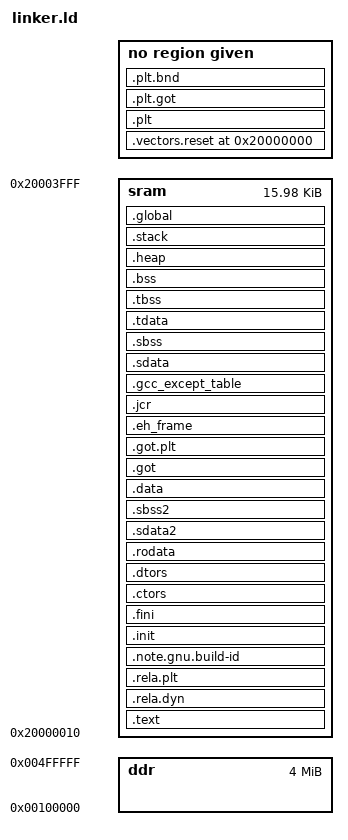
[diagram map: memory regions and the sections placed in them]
_STACK_SIZE = DEFINED(_STACK_SIZE) ? _STACK_SIZE : 0x400;
_HEAP_SIZE = DEFINED(_HEAP_SIZE) ? _HEAP_SIZE : 0x800;

/* Define Memories in the system */

MEMORY
{
   sram : ORIGIN = 0x20000010, LENGTH = 0x3FF0
   ddr : ORIGIN = 0x100000, LENGTH = 4M
}

/* Specify the default entry point to the program */

ENTRY(_start)

/* Define the sections, and where they are mapped in memory */

SECTIONS {

.vectors.reset 0x20000000 : {
   KEEP (*(.vectors.reset))
} 

.text : {
   *(.text)
   *(.text.*)
   *(.gnu.linkonce.t.*)
} > sram

.rela.dyn : {
    *(.rela.init)
    *(.rela.text .rela.text.* .rela.gnu.linkonce.t.*)
    *(.rela.fini)
    *(.rela.rodata .rela.rodata.* .rela.gnu.linkonce.r.*)
    *(.rela.data .rela.data.* .rela.gnu.linkonce.d.*)
    *(.rela.tdata .rela.tdata.* .rela.gnu.linkonce.td.*)
    *(.rela.tbss .rela.tbss.* .rela.gnu.linkonce.tb.*)
    *(.rela.ctors)
    *(.rela.dtors)
    *(.rela.got)
    *(.rela.bss .rela.bss.* .rela.gnu.linkonce.b.*)
    *(.rela.ldata .rela.ldata.* .rela.gnu.linkonce.l.*)
    *(.rela.lbss .rela.lbss.* .rela.gnu.linkonce.lb.*)
    *(.rela.lrodata .rela.lrodata.* .rela.gnu.linkonce.lr.*)
    *(.rela.ifunc)
} > sram

.rela.plt : {
    *(.rela.plt)
    PROVIDE_HIDDEN (__rela_iplt_start = .);
    *(.rela.iplt)
    PROVIDE_HIDDEN (__rela_iplt_end = .);
}  > sram

.plt : {
    *(.plt)
    *(.iplt)
}

.plt.got : {
    *(.plt.got)
}

.plt.bnd : {
    *(.plt.bnd)
}

.note.gnu.build-id : {
   KEEP (*(.note.gnu.build-id))
} > sram

.init : {
   KEEP (*(.init))
} > sram

.fini : {
   KEEP (*(.fini))
} > sram

.ctors : {
   __CTOR_LIST__ = .;
   ___CTORS_LIST___ = .;
   KEEP (*crtbegin.o(.ctors))
   KEEP (*(EXCLUDE_FILE(*crtend.o) .ctors))
   KEEP (*(SORT(.ctors.*)))
   KEEP (*(.ctors))
   __CTOR_END__ = .;
   ___CTORS_END___ = .;
} > sram

.dtors : {
   __DTOR_LIST__ = .;
   ___DTORS_LIST___ = .;
   KEEP (*crtbegin.o(.dtors))
   KEEP (*(EXCLUDE_FILE(*crtend.o) .dtors))
   KEEP (*(SORT(.dtors.*)))
   KEEP (*(.dtors))
   PROVIDE(__DTOR_END__ = .);
   PROVIDE(___DTORS_END___ = .);
} > sram

.rodata : {
   __rodata_start = .;
   *(.rodata)
   *(.rodata.*)
   *(.gnu.linkonce.r.*)
   __rodata_end = .;
} > sram

.sdata2 : {
   . = ALIGN(8);
   __sdata2_start = .;
   *(.sdata2)
   *(.sdata2.*)
   *(.gnu.linkonce.s2.*)
   . = ALIGN(8);
   __sdata2_end = .;
} > sram

.sbss2 : {
   __sbss2_start = .;
   *(.sbss2)
   *(.sbss2.*)
   *(.gnu.linkonce.sb2.*)
   __sbss2_end = .;
} > sram


.data : {
   . = ALIGN(4);
   __data_start = .;
   *(.data)
   *(.data.*)
   *(.gnu.linkonce.d.*)
   __data_end = .;
} > sram

.got : {
    *(.got)
    *(.igot)
} > sram

.got.plt : {
    *(.got.plt)
    *(.igot.plt)
} > sram

.eh_frame : {
   *(.eh_frame)
} > sram

.jcr : {
   *(.jcr)
} > sram

.gcc_except_table : {
   *(.gcc_except_table)
} > sram

.sdata : {
   . = ALIGN(8);
   __sdata_start = .;
   *(.sdata)
   *(.sdata.*)
   *(.gnu.linkonce.s.*)
   __sdata_end = .;
} > sram

.sbss (NOLOAD) : {
   . = ALIGN(4);
   __sbss_start = .;
   *(.sbss)
   *(.sbss.*)
   *(.gnu.linkonce.sb.*)
   . = ALIGN(8);
   __sbss_end = .;
} > sram

.tdata : {
   __tdata_start = .;
   *(.tdata)
   *(.tdata.*)
   *(.gnu.linkonce.td.*)
   __tdata_end = .;
} > sram

.tbss : {
   __tbss_start = .;
   *(.tbss)
   *(.tbss.*)
   *(.gnu.linkonce.tb.*)
   __tbss_end = .;
} > sram

.bss (NOLOAD) : {
   . = ALIGN(4);
   __bss_start = .;
   *(.bss)
   *(.bss.*)
   *(.gnu.linkonce.b.*)
   *(COMMON)
   . = ALIGN(4);
   __bss_end = .;
} > sram

_SDA_BASE_ = __sdata_start + ((__sbss_end - __sdata_start) / 2 );

_SDA2_BASE_ = __sdata2_start + ((__sbss2_end - __sdata2_start) / 2 );

/* Generate Stack and Heap definitions */

.heap (NOLOAD) : {
   . = ALIGN(8);
   _heap = .;
   _heap_start = .;
   . += _HEAP_SIZE;
   _heap_end = .;
}  > sram

.stack (NOLOAD) : {
   _stack_end = .;
   . += _STACK_SIZE;
   . = ALIGN(8);
   _stack = .;
   __stack = _stack;
}  > sram

.global (NOLOAD) : {
    . = ALIGN(8);
    PROVIDE( __global_pointer$ = . );
} > sram

_end = .;
}

